BO_ 1620 CAN_Message_1: 8 BCM
 SG_ SIG_12_05 : 55|16@0+ (0.001,0) [0|5] "V"  ECU,BCM
 SG_ SIG_05 : 39|16@0+ (0.001,0) [0|5] "V"  ECU,BCM
 SG_ SIG_05 : 23|16@0+ (0.001,0) [0|5] "V"  ECU,BCM
 SG_ SIG_05 : 7|16@0+ (0.001,0) [0|5] "V"  ECU,BCM

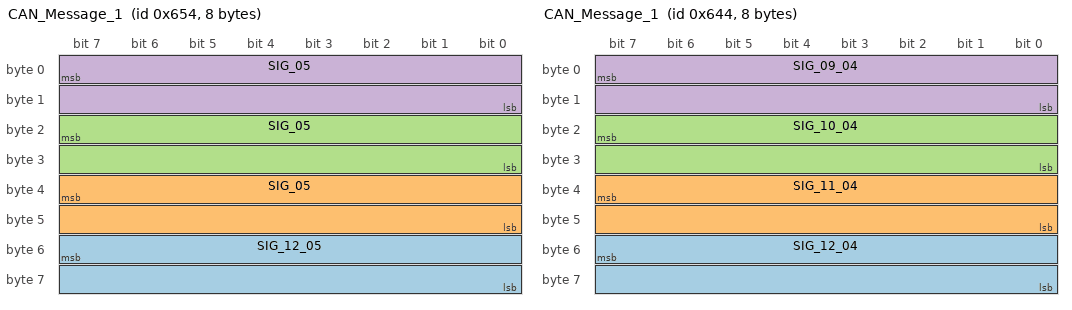
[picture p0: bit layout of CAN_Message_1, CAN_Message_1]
BO_ 1604 CAN_Message_1: 8 BCM
 SG_ SIG_12_04 : 55|16@0+ (0.001,0) [0|5] "V"  ECU,BCM
 SG_ SIG_11_04 : 39|16@0+ (0.001,0) [0|5] "V"  ECU,BCM
 SG_ SIG_10_04 : 23|16@0+ (0.001,0) [0|5] "V"  ECU,BCM
 SG_ SIG_09_04 : 7|16@0+ (0.001,0) [0|5] "V"  ECU,BCM

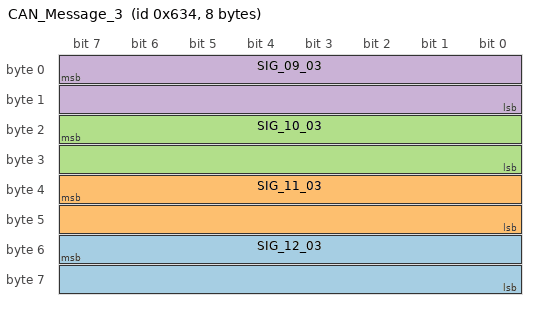
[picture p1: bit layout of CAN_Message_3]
BO_ 1588 CAN_Message_3: 8 BCM
 SG_ SIG_12_03 : 55|16@0+ (0.001,0) [0|5] "V"  ECU,BCM
 SG_ SIG_11_03 : 39|16@0+ (0.001,0) [0|5] "V"  ECU,BCM
 SG_ SIG_10_03 : 23|16@0+ (0.001,0) [0|5] "V"  ECU,BCM
 SG_ SIG_09_03 : 7|16@0+ (0.001,0) [0|5] "V"  ECU,BCM
